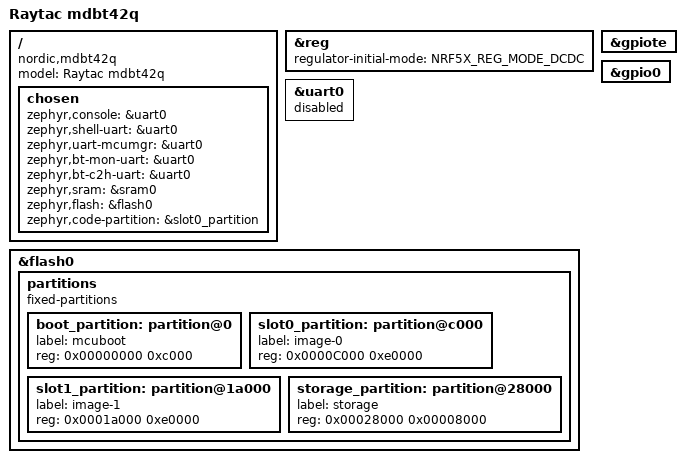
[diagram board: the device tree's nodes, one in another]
/dts-v1/;
#include <nordic/nrf52810_qfaa.dtsi>
#include "mdbt42q_nrf52810-pinctrl.dtsi"
#include <zephyr/dt-bindings/input/input-event-codes.h>

/ {
	model = "Raytac mdbt42q";
	compatible = "nordic,mdbt42q";

	chosen {
		zephyr,console = &uart0;
		zephyr,shell-uart = &uart0;
		zephyr,uart-mcumgr = &uart0;
		zephyr,bt-mon-uart = &uart0;
		zephyr,bt-c2h-uart = &uart0;
		zephyr,sram = &sram0;
		zephyr,flash = &flash0;
		zephyr,code-partition = &slot0_partition;
	};
};

&reg {
	regulator-initial-mode = <NRF5X_REG_MODE_DCDC>;
	status = "okay";
};

&gpiote {
	status = "okay";
};

&gpio0 {
	status = "okay";
};

&uart0 {
        // compatible = "nordic,nrf-uart";
        // current-speed = <115200>;
        // status = "okay";
        // pinctrl-0 = <&uart0_default>;
        // pinctrl-1 = <&uart0_sleep>;
        // pinctrl-names = "default", "sleep";
		status = "disabled";
};

&flash0 {
	partitions {
		compatible = "fixed-partitions";
		#address-cells = <1>;
		#size-cells = <1>;

		boot_partition: partition@0 {
				label = "mcuboot";
				reg = <0x00000000 0xc000>;
		};
		slot0_partition: partition@c000 {
				label = "image-0";
				reg = <0x0000C000 0xe0000>;
		};
		slot1_partition: partition@1a000 {
				label = "image-1";
				reg = <0x0001a000 0xe0000>;
		};
		storage_partition: partition@28000 {
				label = "storage";
				reg = <0x00028000 0x00008000>;
		};
	};
};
